# TZ10xx register map
File version: 0.1g
Registers are 32-bit, read-write, reset 0x0 unless marked. A register's access mark holds for its fields unless they carry their own. Offsets are from the block's base; [hi:lo] are bit positions; {n}, {i} and the like mark numbered series; 'fields as' and 'values as' point back to an identical list; <NAME> marks a mode.

## advtmr
Base 0x40041000
0x00 T0LOAD
  [15:0] Load — Initial or reload value of the counter (0x0001 to 0xFFFF settable) The 0x0000 setting does not operate the counter. Setting any numeric value other than that enables counting. (Note) Writing to this register writes the same value to Timer0BGLoad.
{0x4+0x100*i} T{i}VALUE ro reset 0xFFFF (i=0..3) — T{i} Current value Register
  [15:0] value — Count value of the counter at the current time
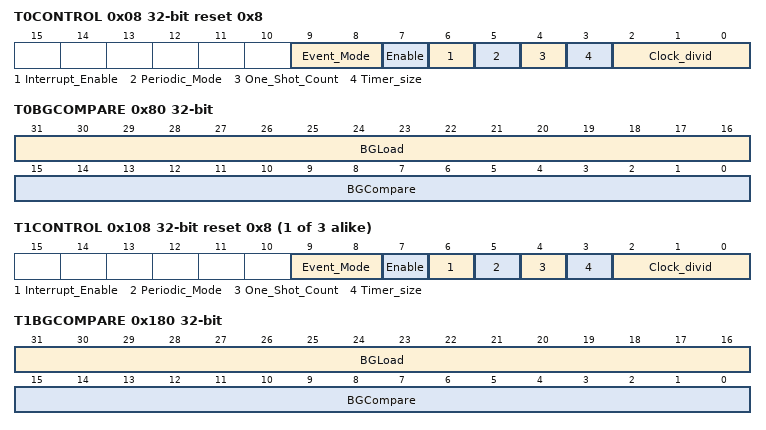
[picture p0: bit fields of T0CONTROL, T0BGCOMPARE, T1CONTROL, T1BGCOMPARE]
0x08 T0CONTROL reset 0x8
  [9:8] Event_Mode — Event counter operation control 0b11: Event timer (event timer) count source: External terminal T0EVCNTSRC 0b10:Event timer (event timer) count source: Internal prescaler 0b0*: Normal timer (normal timer)
  [7] Enable — Timer operation control 1: Enable 0: Disable
  [6] Interrupt_Enable — Interrupt control 1: Interrupt enable 0: Interrupt disable
  [5] Periodic_Mode — Timer operation mode 1: Periodic timer (periodic timer) 0: Free-run timer (free-run timer)
  [4] One_Shot_Count — Timer wrapping/one-shot selection 1: One-shot (one time only) 0: Wrapping (wrapping)
  [3] Timer_size — Timer bit width selection 0x1: Operation as a 16-bit timer 0x0: Operation as an 8-bit timer (high-order bits not used)
  [2:0] Clock_divid — Prescaler (clock frequency division) 0b111: 1/1024 frequency division 0b110: 1/512 frequency division 0b101: 1/128 frequency division 0b100: 1/32 frequency division 0b011: 1/8 frequency division 0b010: 1/4 frequency division 0b001: 1/2 frequency division 0x0: No frequency division (same magnification)
0x0C T0INTCLR — T0 Interrupt clear Register
  [31:0] IntClr — Interrupt clear After the T0TIMINT interrupt occurs, it can be cleared by write access to this register.
0x10 T0RIS ro — T0 Raw Interrupt Status Register
  [0] RIS — A timer interrupt before masking (T0TIMINT) is occurring. (The interrupt occurs when the counter becomes 0x0000.) 1: Interrupt request available 0: No interrupt request
0x14 T0MIS ro — T0 Masked Interrupt Status Register
  [0] MIS — A timer interrupt after masking (T0TIMINT) is occurring. 1: Interrupt request available 0: No interrupt request
0x18 T0BGLOAD — T0 BackGround Load Register
  [15:0] BGLoad — Background Load register A count value set in this register is reloaded after the counter becomes 0x0000 (terminal count). The count value to be reloaded can be changed safely during counting. (Note) Writing to this register does not allow writing to Timer0Load.
0x1C T0INTCNT — T0 Interrupt Count Register
  [7:0] IntCount — Count value for the number of times it became a terminal count of the counter main body. <At read> A count value for the number of times it became a terminal count can be read. <At write> A counter value of Timer0IntCnt can be made to become 0x00 by write access to this register with regard to the timer interrupt generation counter. This register is not cleared by write access of Timer0IntClr. It is not affected by the Timer0Control:Interrupt Enable bit.
0x20 T0CAPTURE ro — T0 Capture value Register
  [15:0] CapReg — Stores a count value when the T0CAPREQ signal is input. If the T0CAPREQ[x] signal is input during capture data reading, the count value is immediately stored after capture data reading ends.
0x40 T0CAPINTCLR — T0 Capture Interrupt clear Register
  [31:0] CapIntClr — After a capture interrupt (T0CAPINT[x]) occurs, it can be cleared by write access to this register.
0x60 T0CAPRIS ro — T0 Capture Raw Interrupt Status Register
  [0] CapRIS — A capture interrupt before masking (T0CAPINT[x]) is occurring. 1: Interrupt request available 0: No interrupt request
0x64 T0CAPMIS ro — T0 Capture Masked Interrupt Status Register
  [0] CapMIS — A capture interrupt after masking (T0CAPINTx) is occurring. 1: Interrupt request available 0: No interrupt request
0x68 T0CAPINTEN — T0 Capture Interrupt Enable Register
  [0] CapIntEn — Capture operation interrupt control 1: Interrupt enable 0: Interrupt disable
0x6C T0CAPEN — T0 Capture Enable Register
  [0] CapEn — Capture operation control 1: Capture enable 0: Capture disable
0x74 T0CAPRELOAD — T0 Capture Reload Register
  [0] CapReload — Capture operation reload control. A counter value is reloaded to Timer0Load(Timer0BGLoad) due to capture generation. 1: Reloads the counter value upon capture generation. 0: Does not reload the counter value upon capture generation.
0x78 T0CAPCTRL — T0 Capture Control Register
  [1:0] CapCtrl0 — Selection of capture input operation 0b11: Capture operation at both the rising and falling edges 0b10: Capture operation at the falling edge 0b01: Capture operation at the rising edge 0b00: Capture operation with pulse input
0x7C T0CAPSYNC — T0 Capture Synchronization Register
  [0] CapSync — Capture input synchronization control 0b1: Synchronizes capture input (for external input with clock not synchronized) 0b0: Does not synchronize capture input (for external input with clock synchronized)
0x80 T0BGCOMPARE — T0 BackGround Compare Register
  [31:16] BGLoad — Background load register This register is the same as the 0x018 register. However, it is write-only. It is set in this area for DMA transfer. It can be accessed only for TCDMASelx=1. (Note) This register appears on the memory map only for TCDMASelx=1. (Note) This register can be accessed from either of the CPU and DMAC. (Note) If this register is accessed in halfword units, a wrong value is written to a register not accessed. So, only access in word units is permitted.
  [15:0] BGCompare — Background compare register that stores a compare value to be compared with a count value A count value set in this register is reloaded after the counter becomes 0 (terminal count). The count value to be reloaded can be changed safely during counting. (Note) Writing to this register does not allow writing to Timer0Compare.
0xA0 T0COMPARE — T0 Compare value Register
  [15:0] CmpReg — Stores a compare value to be compared with a count value. (Note) This register cannot be read immediately after writing to it because a transfer to other clocks (PCLK->TIMCLK) is required. Reading after writing is required for up to one cycle of TIMCLK. (Note) Writing to the Timer0Compare register writes the same value to Timer0BGCompare.
{0xC0+0x100*i} T{i}CMPINTCLR (i=0..3) — T{i} Compare Interrupt clear Register
  [31:0] CmpIntClr — After a compare interrupt occurs, it can be cleared by write access to this register.
0xE0 T0CMPRIS ro — T0 Compare Raw Interrupt Status Register
  [0] CmpRIS — A compare interrupt before masking (T0CMPINTx) is occurring. 1: Interrupt request available 0: No interrupt request
0xE4 T0CMPMIS ro — T0 Compare Masked Interrupt Status Register
  [0] CmpMIS — A compare interrupt after masking (T0CMPINT) is occurring. 1: Interrupt request available 0: No interrupt request
0xE8 T0CMPINTEN — T0 Compare Interrupt Enable Register
  [0] CmpIntEn — Compare operation interrupt control 1: Interrupt enable 0: Interrupt disable
0xEC T0CMPEN — T0 Compare Enable Register
  [0] CmpEn — Compare operation control 1: Compare enable 0: Compare disable
{0x0+0x100*i} T{i}LOAD (i=1..3)
  [15:0] Load — Initial or reload value of the counter (0x0001 to 0xFFFF settable)
{0x8+0x100*i} T{i}CONTROL reset 0x8 (i=1..3)
  [9:8] Event_Mode — Event counter operation control
  [7] Enable — Timer operation control
  [6] Interrupt_Enable — Interrupt control
  [5] Periodic_Mode — Timer operation mode
  [4] One_Shot_Count — Selection of timer wrapping and one-shot
  [3] Timer_size — Selection of timer bit width
  [2:0] Clock_divid — Prescaler (clock frequency division)
{0xC+0x100*i} T{i}INTCLR (i=1..3) — T{i} Interrupt clear Register
  [31:0] IntClr — Interrupt clear
{0x10+0x100*i} T{i}RIS ro (i=1..3) — T{i} Raw Interrupt Status Register
  [0] RIS — A timer interrupt before masking (T{i}TIMINT) is occurring. (The interrupt occurs when the counter becomes 0x0000.)
{0x14+0x100*i} T{i}MIS ro (i=1..3) — T{i} Masked Interrupt Status Register
  [0] MIS — A timer interrupt after masking (T{i}TIMINT) is occurring.
0x118 T1BGLOAD — T1 BackGround Load Register
  [15:0] BGLoad — Background Load register
{0x1C+0x100*i} T{i}INTCNT (i=1..3) — T{i} Interrupt Count Register
  [7:0] IntCount — Count value for the number of times it became a terminal count of the counter main body
{0x20+0x100*i} T{i}CAPTURE ro (i=1..3) — T{i} Capture value Register
  [15:0] CapReg — Stores a count value when the T{i}CAPREQ signal is input.
{0x40+0x100*i} T{i}CAPINTCLR (i=1..3) — T{i} Capture Interrupt clear Register
  [31:0] CapIntClr — After a capture interrupt occurs, it can be cleared by write access to this register.
{0x60+0x100*i} T{i}CAPRIS ro (i=1..3) — T{i} Capture Raw Interrupt Status Register
  [0] CapRIS — A capture interrupt before masking (T{i}CAPINT[x]) is occurring.
{0x64+0x100*i} T{i}CAPMIS ro (i=1..3) — T{i} Capture Masked Interrupt Status Register
  [0] CapMIS — A capture interrupt after masking (T{i}CAPINTx) is occurring.
{0x68+0x100*i} T{i}CAPINTEN (i=1..3) — T{i} Capture Interrupt Enable Register
  [0] CapIntEn — Capture operation interrupt control
{0x6C+0x100*i} T{i}CAPEN (i=1..3) — T{i} Capture Enable Register
  [0] CapEn — Capture operation control
{0x74+0x100*i} T{i}CAPRELOAD (i=1..3) — T{i} Capture Reload Register
  [0] CapReload — Capture operation reload control. A counter value is reloaded to Timer{i}Load(Timer{i}BGLoad) due to capture generation.
{0x78+0x100*i} T{i}CAPCTRL (i=1..3) — T{i} Capture Control Register
  [1:0] CapCtrl0 — Capture input operation selection
{0x7C+0x100*i} T{i}CAPSYNC (i=1..3) — T{i} Capture Synchronization Register
  [0] CapSync — Capture input synchronization control
0x180 T1BGCOMPARE — T1 BackGround Compare Register
  [31:16] BGLoad — Background Load register
  [15:0] BGCompare — Background compare register. Stores a compare value to be compared with a count value.
{0xA0+0x100*i} T{i}COMPARE (i=1..3) — T{i} Compare value Register
  [15:0] CmpReg — Stores a compare value to be compared with a count value.
{0xE0+0x100*i} T{i}CMPRIS ro (i=1..3) — T{i} Compare Raw Interrupt Status Register
  [0] CmpRIS — A compare interrupt before masking (T{i}CMPINTx) is occurring.
0x1E4 T1CMPMIS ro — T1 Compare Masked Interrupt Status Register
  [0] CmpMIS — A compare interrupt before masking (T1CMPINT) is occurring.
{0xE8+0x100*i} T{i}CMPINTEN (i=1..3) — T{i} Compare Interrupt Enable Register
  [0] CmpIntEn — Compare operation interrupt control
{0xEC+0x100*i} T{i}CMPEN (i=1..3) — T{i} Compare Enable Register
  [0] CmpEn — Compare operation control
0x218 T2BGLOAD — T2 BackGround Load Register
  [15:0] BGLoad — Background Load register
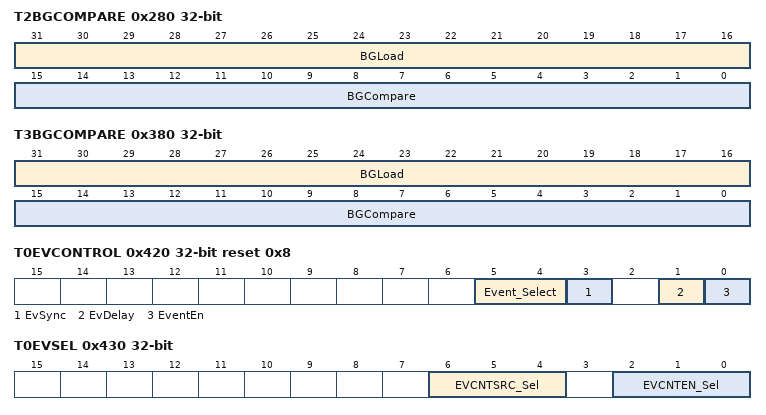
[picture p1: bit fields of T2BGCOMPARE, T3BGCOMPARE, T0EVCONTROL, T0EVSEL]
0x280 T2BGCOMPARE — T2 BackGround Compare Register
  fields as T1BGCOMPARE
0x2E4 T2CMPMIS ro — T2 Compare Masked Interrupt Status Register
  [0] CmpMIS — A compare interrupt after masking (T2CMPINT) is occurring.
0x318 T3BGLOAD — T3 BackGround Load Register
  [15:0] BGLoad — Background load register
0x380 T3BGCOMPARE — T3 BackGround Compare Register
  [31:16] BGLoad — Background load register
  [15:0] BGCompare — Background compare register. Stores a compare value to be compared with a count value.
0x3E4 T3CMPMIS ro — T3 Compare Masked Interrupt Status Register
  [0] CmpMIS — A compare interrupt after masking (T3CMPINT) is occurring.
0x400 T0TFFEN — T0 TFF Enable Register
  [0] TFFEn — TFF (Toggle Flip-Flop) operation control 1: TFF function enable 0: TFF function disable (TFF output is fixed at 0.)
0x404 T0TFFSTAT ro — T0 TFF Status Register
  [0] TFFStat — TFF (Toggle Flip-Flop) output status (indicating the status before the last stage of Timer0TFFInv) 1: High TFF output 0: Low TFF output
0x408 T0TFFZERO
  [0] TFFZero — TFF (Toggle Flip-Flop) operation control (to select whether to toggle TFF at a falling edge when the Timer counter is 0) This setting is required for PWM operation. 1: Toggle with Compare and Timer counter 0x0000 (terminal count) (the Timer0TFFCtrl setting disabled) 0: Toggle only with Compare (the Timer0TFFCtrl setting enabled)
0x40C T0TFFINV — T0 TFF Invert Register
  [0] TFFInv — TFF (Toggle Flip-Flop) operation control (to select whether the output is reversed at its last stage) 1: Reverses the TFF output at its last stage for output. 0: TFF output without reverse.
0x410 T0TFFCTRL reset 0x3 — T0 TFF Control Register
  [1:0] TFFCtrl — Selection of TFF (Toggle Flip-Flop) output operation 0b11: Pulse operation. Compare output becomes TFF output as is. 0b10: Toggle operation. TFF output is reversed for the relevant Compare output. 0b01: Operation for becoming "1". No change for TFF=1. 0b00: Operation for becoming "0". No change for TFF=0.
0x414 T0TFFINIT — T0 TFF Iniit Register
  [0] TFFInit — TFF (Toggle Flip-Flop) operation control (selection of output initial value) 1: Sets the initial value of TFF output to 1. 0: Sets the initial value of TFF output to 0.
0x420 T0EVCONTROL reset 0x8 — T0 Event Control Register
  [5:4] Event_Select — Event counter operation selection 0b11: EventEn + external terminal input (edge) 0b10: EventEn + external terminal input (level) 0b0*: EventEn bit only
  [3] EvSync — Selection of event counter input synchronization 1: Synchronized 0: Not synchronized
  [1] EvDelay — Selection of count start delay of the event counter 1: Start delay by 1 TIMCLK 0: No start delay
  [0] EventEn — Event counter control 1: Event counter enable 0: Event counter disable
0x430 T0EVSEL — T0 EV Select Control Register
  [6:4] EVCNTSRC_Sel — EVCNTSRC I/O control Input selection signal: Generation of the output level of the T0EVSRCSEL signals. 0b111:ADVTMR:T3TFFOUT 0b110:ADVTMR:T2TFFOUT 0b101:ADVTMR:T1TFFOUT 0b100:ADVTMR:T3TIMINT(ch3->ch0 cascade connect) 0b011:PIN:MCU_I2C0_CLK(Pin share=FMOD2) 0b010:PIN:MCU_I2C0_DATA(Pin share=FMOD2) 0b001:PIN:MCU_UA0_TXD(Pin share=FMOD2) , PIN:MCU_GPIO_13(Pin share=FMOD3) 0b000:PIN:MCU_UA0_RXD(Pin share=FMOD2) , PIN:MCU_GPIO_12(Pin share=FMOD3)
  [2:0] EVCNTEN_Sel — EVCNTEN I/O control Input selection signal: Generation of the output level of the T0EVENSEL signals. 0b111:ADVTMR:T3TFFOUT 0b110:ADVTMR:T2TFFOUT 0b101:ADVTMR:T1TFFOUT 0b100:ADVTMR:T3TIMINT(ch3->ch0 cascade connect) 0b011:PIN:MCU_I2C0_CLK(Pin share=FMOD2) 0b010:PIN:MCU_I2C0_DATA(Pin share=FMOD2) 0b001:PIN:MCU_UA0_TXD(Pin share=FMOD2) , PIN:MCU_GPIO_13(Pin share=FMOD3) 0b000:PIN:MCU_UA0_RXD(Pin share=FMOD2) , PIN:MCU_GPIO_12(Pin share=FMOD3)
{0x434+0x100*i} T{i}IOSEL (i=0..2) — T{i} IO Select Control Register
  [0] IOSel — T{i}TFFOUT I/O control 1: T{i}TFFOUT output 0: Input from external pin or not output
0x438 T0CAPSEL — T0 Capture Select Register
  [2:0] CapSel — Capture input selection Input selection signal: Generates the output level of the T0CAPSEL signals. 0b111:ADVTMR:T3TFFOUT 0b110:ADVTMR:T2TFFOUT 0b101:ADVTMR:T1TFFOUT 0b100:EVM:evm_advtimer_capture[0] 0b011:PIN:MCU_I2C0_CLK(Pin share=FMOD2) 0b010:PIN:MCU_I2C0_DATA(Pin share=FMOD2) 0b001:PIN:MCU_UA0_TXD(Pin share=FMOD2) , PIN:MCU_GPIO_13(Pin share=FMOD3) 0b000:PIN:MCU_UA0_RXD(Pin share=FMOD2) , PIN:MCU_GPIO_12(Pin share=FMOD3)
0x480 T0CAPDMAEN — T0 CapDMA Enable Register
  [0] CapDMAEn — T0CAPDMAREQ control 1: CapDMA request enable 0: CapDMA request disable
0x490 T0CAPDMASTAT ro — T0 CapDMA Status Register
  [0] CapDMAStat — CapDMA transfer status After start of DMA transfer, status "1" continues until T0CAPDMACTC arrives. It changes to "0" after T0CAPDMACTC arrives. 1: DMA request in progress 0: No DMA request
0x498 T0CMPDMASTAT — T0 CmpDMA Status Register
  [0] CmpDMAStat — CmpDMA transfer status After start of DMA transfer, status "1" continues until T0CMPDMACTC arrives. It changes to "0" after T0CMPDMACTC arrives. 1: DMA request in progress 0: No DMA request
0x49C T0TCDMASEL — T0 Terminal Count DMA Request Select Register
  [0] TCDMASel — Selection of a T0CMPDMAREQ signal request condition 1: Sets a T0CMPDMAREQ signal request at terminal count occurrence. 0: Sets a T0CMPDMAREQ signal request at compare occurrence.
0x4A0 T0CMPDMAEN — T0 CmpDMA Enable Register
  [0] CmpDMAEn — T0CMPDMAREQ control 1: CmpDMA request enable 0: CmpDMA request disable
0x4B8 T0CAPDMASYNC — T0 CapDMAC signals Synchronization Register
  [0] CapDMASync — Synchronization control of T0CAPDMACLR and T0CAPDMATC 1: Synchronizes input (for external input with clock not synchronized) 0: Does not synchronize input (for external input with clock synchronized)
0x4BC T0CMPDMASYNC — T0 CmpDMAC signals Synchronization Register
  [0] CmpDMASync — Synchronization control of T0CMPDMACLR and T0CMPDMATC 1: Synchronizes input (for external input with clock not synchronized) 0: Does not synchronize input (for external input with clock synchronized)
0x4F0 T0CAPDMACLR — T0 CapDMA clear Register
  [0] CapDMAClr — Can forcibly clear a generated CapDMA request. 1: Clears the DMA request. 0: Does nothing. (The request can be cleared only for CAPDMAEN=1.)
0x4F4 T0CMPDMACLR — T0 CmpDMA clear Register
  [0] CmpDMAClr — Can forcibly clear a generated CmpDMA request. 1: Clears the DMA request. 0: Does nothing. (The request can be cleared only for CMPDMAEN=1.)
{0x400+0x100*i} T{i}TFFEN (i=1..3) — T{i} TFF Enable Register
  [0] TFFEn — TFF (Toggle Flip-Flop) operation control
{0x404+0x100*i} T{i}TFFSTAT ro (i=1..3) — T{i} TFF Status Register
  [0] TFFStat — TFF (Toggle Flip-Flop) output status (indicating the status before the last stage of Timer{i}TFFInv)
{0x408+0x100*i} T{i}TFFZERO (i=1..3)
  [0] TFFZero — TFF (Toggle Flip-Flop) operation control (selection of whether or not TFF is toggled at the falling edge when the timer counter is 0)
{0x40C+0x100*i} T{i}TFFINV (i=1..3) — T{i} TFF Invert Register
  [0] TFFInv — TFF (Toggle Flip-Flop) operation control (selection of whether or not the output is reversed at its last stage)
{0x410+0x100*i} T{i}TFFCTRL reset 0x3 (i=1..3) — T{i} TFF Control Register
  [1:0] TFFCtrl — Selection of TFF (Toggle Flip-Flop) output operation
{0x414+0x100*i} T{i}TFFINIT (i=1..3) — T{i} TFF Iniit Register
  [0] TFFInit — TFF (Toggle Flip-Flop) operation control (selection of output initial value)
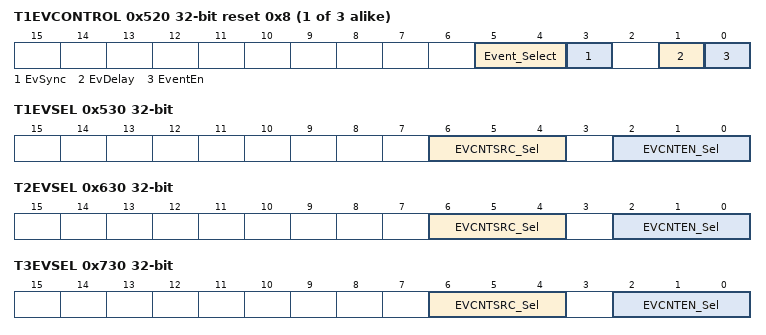
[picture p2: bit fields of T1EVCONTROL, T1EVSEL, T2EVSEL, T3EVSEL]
{0x420+0x100*i} T{i}EVCONTROL reset 0x8 (i=1..3) — T{i} Event Control Register
  [5:4] Event_Select — Event counter operation selection
  [3] EvSync — Selection of event counter input synchronization
  [1] EvDelay — Selection of event counter count start delay
  [0] EventEn — Event counter control
0x530 T1EVSEL — T1 EV Select Control Register
  [6:4] EVCNTSRC_Sel — EVCNTSRC I/O control Input selection signal: Generation of the output level of the T1EVSRCSEL signals. 0b111:ADVTMR:T3TFFOUT 0b110:ADVTMR:T2TFFOUT 0b101:ADVTMR:T0TIMINT(ch0->ch1 cascade connect) 0b100:ADVTMR:T0TFFOUT 0b011:PIN:MCU_I2C0_CLK(Pin share=FMOD2) 0b010:PIN:MCU_I2C0_DATA(Pin share=FMOD2) 0b001:PIN:MCU_UA0_TXD(Pin share=FMOD2) , PIN:MCU_GPIO_13(Pin share=FMOD3) 0b000:PIN:MCU_UA0_RXD(Pin share=FMOD2) , PIN:MCU_GPIO_12(Pin share=FMOD3)
  [2:0] EVCNTEN_Sel — EVCNTEN I/O control Input selection signal: Generation of the output level of the T1EVENSEL signals. 0b111:ADVTMR:T3TFFOUT 0b110:ADVTMR:T2TFFOUT 0b101:ADVTMR:T0TIMINT(ch0->ch1 cascade connect) 0b100:ADVTMR:T0TFFOUT 0b011:PIN:MCU_I2C0_CLK(Pin share=FMOD2) 0b010:PIN:MCU_I2C0_DATA(Pin share=FMOD2) 0b001:PIN:MCU_UA0_TXD(Pin share=FMOD2) , PIN:MCU_GPIO_13(Pin share=FMOD3) 0b000:PIN:MCU_UA0_RXD(Pin share=FMOD2) , PIN:MCU_GPIO_12(Pin share=FMOD3)
0x538 T1CAPSEL — T1 Capture Select Register
  [2:0] CapSel — Capture input selection Input selection signal: Generates the output level of the T1CAPSEL signals. 0b111:ADVTMR:T3TFFOUT 0b110:ADVTMR:T2TFFOUT 0b101:EVM:evm_advtimer_capture[1] 0b100:ADVTMR:T0TFFOUT 0b011:PIN:MCU_I2C0_CLK(Pin share=FMOD2) 0b010:PIN:MCU_I2C0_DATA(Pin share=FMOD2) 0b001:PIN:MCU_UA0_TXD(Pin share=FMOD2) , PIN:MCU_GPIO_13(Pin share=FMOD3) 0b000:PIN:MCU_UA0_RXD(Pin share=FMOD2) , PIN:MCU_GPIO_12(Pin share=FMOD3)
0x580 T1CAPDMAEN — T1 CapDMA Enable Register
  [0] CapDMAEn — T1CAPDMAREQ control
{0x490+0x100*i} T{i}CAPDMASTAT ro (i=1..3) — T{i} CapDMA Status Register
  [0] CapDMAStat — CapDMA transfer status
{0x498+0x100*i} T{i}CMPDMASTAT ro (i=1..3) — T{i} CmpDMA Status Register
  [0] CmpDMAStat — CmpDMA transfer status
{0x49C+0x100*i} T{i}TCDMASEL (i=1..3) — T{i} Terminal Count DMA Request Select Register
  [0] TCDMASel — Selection of a T{i}CMPDMAREQ signal request condition
{0x4A0+0x100*i} T{i}CMPDMAEN (i=1..3) — T{i} CmpDMA Enable Register
  [0] CmpDMAEn — T{i}CMPDMAREQ control
{0x4B8+0x100*i} T{i}CAPDMASYNC (i=1..3) — T{i} CapDMAC signals Synchronization Register
  [0] CapDMASync — Synchronization control of T{i}CAPDMACLR and T{i}CAPDMATC inputs
{0x4BC+0x100*i} T{i}CMPDMASYNC (i=1..3) — T{i} CmpDMAC signals Synchronization Register
  [0] CmpDMASync — Synchronization control of T{i}CMPDMACLR and T{i}CMPDMATC inputs
{0x4F0+0x100*i} T{i}CAPDMACLR (i=1..3) — T{i} CapDMA clear Register
  [0] CapDMAClr — Can clear a CapDMA request forcibly.
{0x4F4+0x100*i} T{i}CMPDMACLR (i=1..3) — T{i} CmpDMA clear Register
  [0] CmpDMAClr — Can clear a CmpDMA request forcibly.
0x630 T2EVSEL — T2 EV Select Control Register
  [6:4] EVCNTSRC_Sel — EVCNTSRC I/O control Input selection signal: Generation of the output level of the T2EVSRCSEL signals. 0b111:ADVTMR:T3TFFOUT 0b110:ADVTMR:T1TIMINT(ch1->ch2 cascade connect) 0b101:ADVTMR:T1TFFOUT 0b100:ADVTMR:T0TFFOUT 0b011:PIN:MCU_I2C0_CLK(Pin share=FMOD2) 0b010:PIN:MCU_I2C0_DATA(Pin share=FMOD2) 0b001:PIN:MCU_UA0_TXD(Pin share=FMOD2) , PIN:MCU_GPIO_13(Pin share=FMOD3) 0b000:PIN:MCU_UA0_RXD(Pin share=FMOD2) , PIN:MCU_GPIO_12(Pin share=FMOD3)
  [2:0] EVCNTEN_Sel — EVCNTEN I/O control Input selection signal: Generation of the output level of the T2EVENSEL signals. 0b111:ADVTMR:T3TFFOUT 0b110:ADVTMR:T1TIMINT(ch1->ch2 cascade connect) 0b101:ADVTMR:T1TFFOUT 0b100:ADVTMR:T0TFFOUT 0b011:PIN:MCU_I2C0_CLK(Pin share=FMOD2) 0b010:PIN:MCU_I2C0_DATA(Pin share=FMOD2) 0b001:PIN:MCU_UA0_TXD(Pin share=FMOD2) , PIN:MCU_GPIO_13(Pin share=FMOD3) 0b000:PIN:MCU_UA0_RXD(Pin share=FMOD2) , PIN:MCU_GPIO_12(Pin share=FMOD3)
0x638 T2CAPSEL — T2 Capture Select Register
  [2:0] CapSel — Capture input selection Input selection signal: Generates the output level of the T2CAPSEL signals. 0b111:ADVTMR:T3TFFOUT 0b110:EVM:evm_advtimer_capture[2] 0b101:ADVTMR:T1TFFOUT 0b100:ADVTMR:T0TFFOUT 0b011:PIN:MCU_I2C0_CLK(Pin share=FMOD2) 0b010:PIN:MCU_I2C0_DATA(Pin share=FMOD2) 0b001:PIN:MCU_UA0_TXD(Pin share=FMOD2) , PIN:MCU_GPIO_13(Pin share=FMOD3) 0b000:PIN:MCU_UA0_RXD(Pin share=FMOD2) , PIN:MCU_GPIO_12(Pin share=FMOD3)
0x680 T2CAPDMAEN — T2 CapDMA Enable Register
  [0] CapDMAEn — T2CAPDMAREQ control
0x730 T3EVSEL — T3 EV Select Control Register
  [6:4] EVCNTSRC_Sel — EVCNTSRC I/O control Input selection signal: Generation of the output level of the T3EVSRCSEL signals. 0b111:ADVTMR:T2TIMINT(ch2->ch3 cascade connect) 0b110:ADVTMR:T2TFFOUT 0b101:ADVTMR:T1TFFOUT 0b100:ADVTMR:T0TFFOUT 0b011:PIN:MCU_I2C0_CLK(Pin share=FMOD2) 0b010:PIN:MCU_I2C0_DATA(Pin share=FMOD2) 0b001:PIN:MCU_UA0_TXD(Pin share=FMOD2) , PIN:MCU_GPIO_13(Pin share=FMOD3) 0b000:PIN:MCU_UA0_RXD(Pin share=FMOD2) , PIN:MCU_GPIO_12(Pin share=FMOD3)
  [2:0] EVCNTEN_Sel — EVCNTEN I/O control Input selection signal: Generation of the output level of the T3EVENSEL signals. 0b111:ADVTMR:T3TFFOUT 0b110:ADVTMR:T2TFFOUT 0b101:ADVTMR:T1TFFOUT 0b100:ADVTMR:T0TFFOUT 0b011:PIN:MCU_I2C0_CLK(Pin share=FMOD2) 0b010:PIN:MCU_I2C0_DATA(Pin share=FMOD2) 0b001:PIN:MCU_UA0_TXD(Pin share=FMOD2) , PIN:MCU_GPIO_13(Pin share=FMOD3) 0b000:PIN:MCU_UA0_RXD(Pin share=FMOD2) , PIN:MCU_GPIO_12(Pin share=FMOD3)
0x734 T3IOSEL — T3 IO Select Control Register
  [0] IOSel — T3TFFOUT I/O control
0x738 T3CAPSEL — T3 Capture Select Register
  [2:0] CapSel — Capture input selection Input selection signal: Generates the output level of the T3CAPSEL signals. 0b111:EVM:evm_advtimer_capture[3] 0b110:ADVTMR:T3TFFOUT 0b101:ADVTMR:T1TFFOUT 0b100:ADVTMR:T0TFFOUT 0b011:PIN:MCU_I2C0_CLK(Pin share=FMOD2) 0b010:PIN:MCU_I2C0_DATA(Pin share=FMOD2) 0b001:PIN:MCU_UA0_TXD(Pin share=FMOD2) , PIN:MCU_GPIO_13(Pin share=FMOD3) 0b000:PIN:MCU_UA0_RXD(Pin share=FMOD2) , PIN:MCU_GPIO_12(Pin share=FMOD3)
0x780 T3CAPDMAEN — T3 CapDMA Enable Register
  [0] CapDMAEn — T3CAPDMAREQ control 1: T3TFFOUT output 0: Input from external pin or not output
0xF00 TITCR — Timer Integration test control Register
  [0] Test_Mode_Enable — Test mode control 1: Test mode status 0: Normal operation status
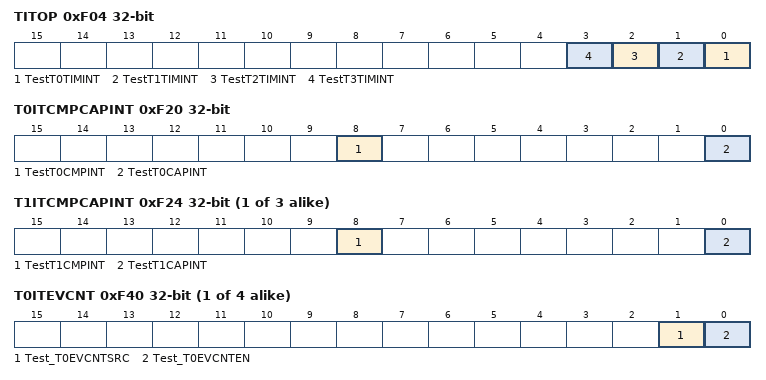
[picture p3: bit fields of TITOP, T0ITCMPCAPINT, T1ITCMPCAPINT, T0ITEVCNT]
0xF04 TITOP — Timer Integration test output set Register
  [n] TestT{n}TIMINT (n=0..3) — T{n}TIMINT signal output (only in test mode) 1: T{n}TIMINT="1" 0: T{n}TIMINT="0"
0xF10 TOTSYNC reset 0xFF — Timer Other Timer Synchronization Register
  [7:0] OTSync — Controls TIMCLKEN of other timers. The timer that can be controlled depends on connection. To establish synchronization with multiple timers, OTSYNC[x] output from this timer should be connected to TxTIMCLKEN of each timer. TxTIMCLKEN of this timer should be connected to OTSYNC[x]. Each timer should have the same setting value. The timer can be synchronously operated by writing 1 to connected OTSYNC[x:x] at the same time. (The following shows a connection of TZ1000.) OTSYNC[0]-->ADVTMR:T0TIMCLKEN OTSYNC[1]-->ADVTMR:T1TIMCLKEN OTSYNC[2]-->ADVTMR:T2TIMCLKEN OTSYNC[3]-->ADVTMR:T3TIMCLKEN OTSYNC[4]-->not connect OTSYNC[5]-->not connect OTSYNC[6]-->not connect OTSYNC[7]-->not connect
0xF20 T0ITCMPCAPINT — T0 ITCompare_Capture Interrupt set Register
  [8] TestT0CMPINT — T0CMPINT output control 1: T0CMPINT="1" 0: T0CMPINT="0"
  [0] TestT0CAPINT — T0CAPINT output control 1: T0CAMPINT="1" 0: T0CAPINT="0"
{0xF20+4i} T{i}ITCMPCAPINT (i=1..3) — T{i} ITCompare_Capture Interrupt set Register
  [8] TestT{i}CMPINT — T{i}CMPINT output control 1: T{i}CMPINT="1" 0: T{i}CMPINT="0"
  [0] TestT{i}CAPINT — T{i}CAPINT output control 1: T{i}CAPINT="1" 0: T{i}CAPINT="0"
{0xF40+4i} T{i}ITEVCNT ro (i=0..3) — T{i} ITEVCNT Input Register
  [1] Test_T{i}EVCNTSRC — T{i}EVCNTSRC input status 1: T{i}EVCNTSRC="1" 0: T{i}EVCNTSRC="0"
  [0] Test_T{i}EVCNTEN — T{i}EVCNTEN input status 1: T{i}EVCNTEN="1" 0: T{i}EVCNTEN="0"
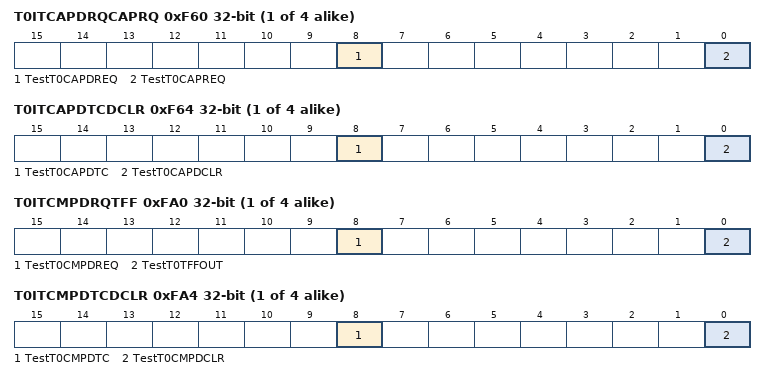
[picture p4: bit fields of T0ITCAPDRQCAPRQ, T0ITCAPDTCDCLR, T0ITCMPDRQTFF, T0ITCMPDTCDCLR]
{0xF60+8i} T{i}ITCAPDRQCAPRQ (i=0..3) — T{i} ITCAPDMAREQ_CAPREQ Register
  [8] TestT{i}CAPDREQ — T{i}CAPDREQ output control 1: T{i}CAPDMAREQ="1" 0: T{i}CAPDMAREQ="0"
  [0] TestT{i}CAPREQ ro — T{i}CAPREQ input status 1: T{i}CAPREQ="1" 0: T{i}CAPREQ="0"
{0xF64+8i} T{i}ITCAPDTCDCLR ro (i=0..3) — T{i} ITCAPDMATC_CAPDMACLR Register
  [8] TestT{i}CAPDTC — T{i}CAPDTC input status 1: T{i}CAPDMATC="1" 0: T{i}CAPDMATC="0"
  [0] TestT{i}CAPDCLR — T{i}CAPDCLR input status 1: T{i}CAPDMACLR="1" 0: T{i}CAPDMACLR="0"
{0xFA0+8i} T{i}ITCMPDRQTFF (i=0..3) — T{i} ITCMPDMAREQ_TFFOUT Register
  [8] TestT{i}CMPDREQ — T{i}CMPDREQ output control 1: T{i}CMPDMAREQ="1" 0: T{i}CMPDMAREQ="0"
  [0] TestT{i}TFFOUT — T{i}TFFOUT output control 1: T{i}TFFOUT="1" 0: T{i}TFFOUT="0"
{0xFA4+8i} T{i}ITCMPDTCDCLR ro (i=0..3) — T{i} ITCMPDMATC_CMPDMACLR Register
  [8] TestT{i}CMPDTC — T{i}CMPDTC input status 1: T{i}CMPDMATC="1" 0: T{i}CMPDMATC="0"
  [0] TestT{i}CMPDCLR — T{i}CMPDCLR input status 1: T{i}CMPDMACLR="1" 0: T{i}CMPDMACLR="0"
0xFE0 TPERIPHID0 ro reset 0x4 — Timer Peripheral ID0 Register
  [7:0] Partnumber0 — Peripheral ID (this register stores a value from a hardware viewpoint.) Partnumber(Lower) SP804=>04
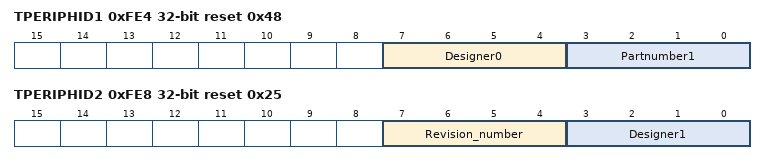
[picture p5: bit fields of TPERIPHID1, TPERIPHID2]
0xFE4 TPERIPHID1 ro reset 0x48 — Timer Peripheral ID1 Register
  [7:4] Designer0 — Peripheral ID (this register stores a value from a hardware viewpoint.) Designer(Lower) 54=>4
  [3:0] Partnumber1 — Peripheral ID (this register stores a value from a hardware viewpoint.) Partnumber(Lower) SP804=>8
0xFE8 TPERIPHID2 ro reset 0x25 — Timer Peripheral ID2 Register
  [7:4] Revision_number — Peripheral ID (this register stores a value from a hardware viewpoint.) Revision: 2nd=>2
  [3:0] Designer1 — Peripheral ID (this register stores a value from a hardware viewpoint.) Designer(Upper) 54=>5
0xFEC TPERIPHID3 ro reset 0x216 — Timer Peripheral ID3 Register
  [15:0] Configuration — Peripheral ID (this register stores a value from a hardware viewpoint.) Configuration: ba6 => 0216
0xFF0 TPCELLID0 ro reset 0xD — Timer PrimeCell ID0 Register
  [7:0] ADVTMR_TPCellID0 — Peripheral ID (this register stores a value from a hardware viewpoint.)
0xFF4 TPCELLID1 ro reset 0xF0 — Timer PrimeCell ID1 Register
  [7:0] ADVTMR_TPCellID1 — Peripheral ID (this register stores a value from a hardware viewpoint.)
0xFF8 TPCELLID2 ro reset 0x5 — Timer PrimeCell ID2 Register
  [7:0] ADVTMR_TPCellID2 — Peripheral ID (this register stores a value from a hardware viewpoint.)
0xFFC TPCELLID3 ro reset 0xB1 — Timer PrimeCell ID3 Register
  [7:0] TimerPCellID3 — Peripheral ID (this register stores a value from a hardware viewpoint.)
